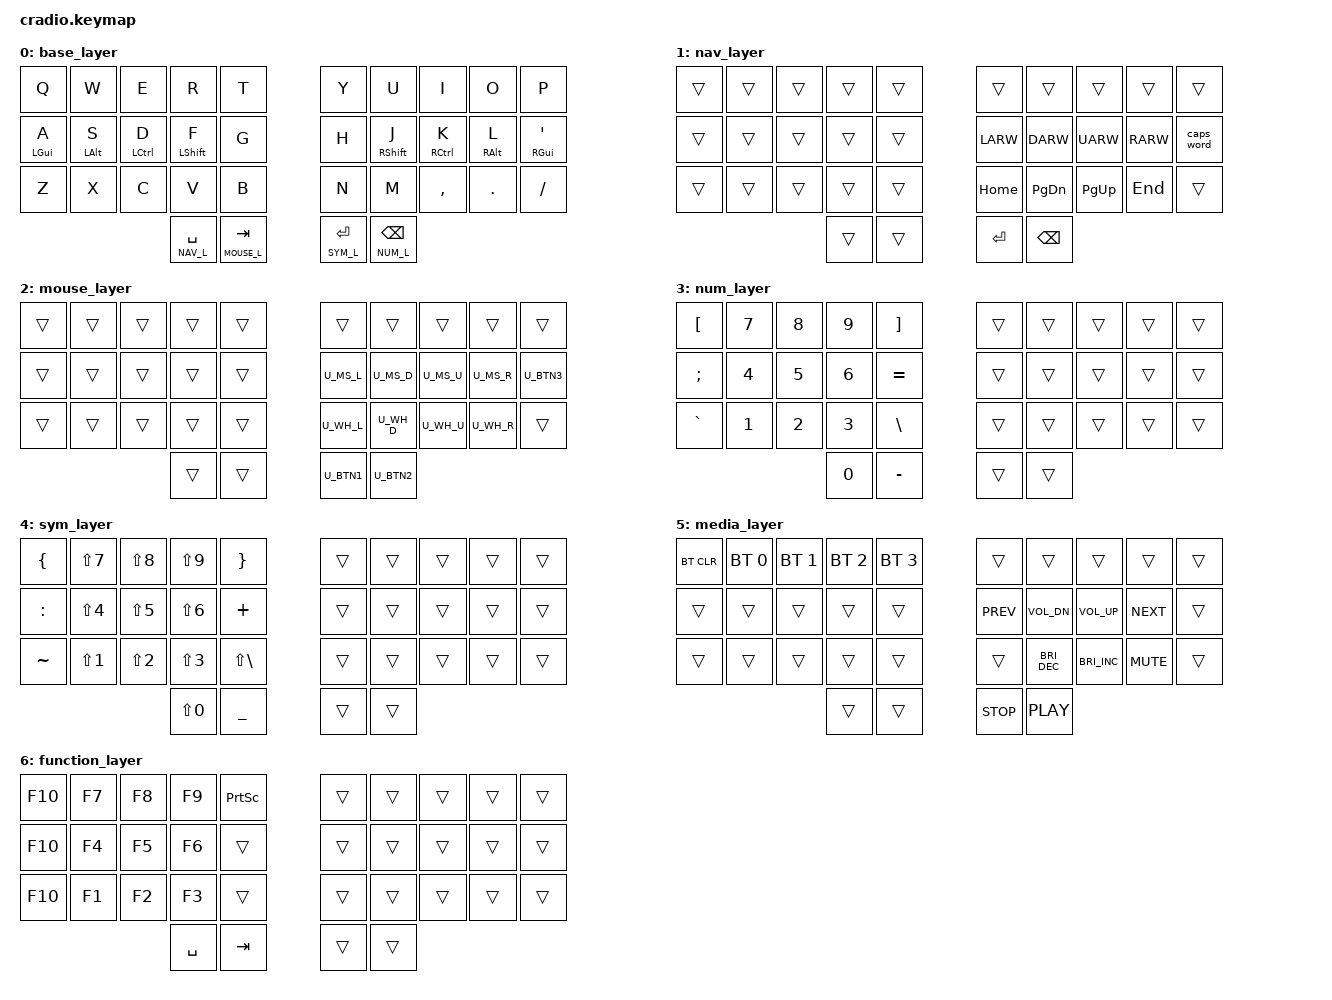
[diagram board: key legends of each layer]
/*
 * Copyright (c) 2020 The ZMK Contributors
 *
 * SPDX-License-Identifier: MIT
 */

#include <behaviors.dtsi>
#include <dt-bindings/zmk/keys.h>
#include <dt-bindings/zmk/bt.h>

#include "mouse.dtsi"
#include "combos.dtsi"

#include "../zmk-nodefree-config/keypos_def/keypos_34keys.h"
#define KEYS_L LT0 LT1 LT2 LT3 LT4 LM0 LM1 LM2 LM3 LM4 LB0 LB1 LB2 LB3 LB4 
#define KEYS_R RT0 RT1 RT2 RT3 RT4 RM0 RM1 RM2 RM3 RM4 RB0 RB1 RB2 RB3 RB4 
#define KEYS_T LH0 LH1 RH0 RH1 

// Layers Number
#define BASE_L 0
#define NAV_L 1
#define MOUSE_L 2
#define NUM_L 3
#define SYM_L 4
#define MEDIA_L 5
#define FUNC_L 6

// Using layer taps on thumbs, having quick tap as well helps w/ repeating space/backspace
&lt {
    tapping-term-ms = <175>; 
    quick-tap-ms = <200>;
};

/ {
    behaviors {
        hml: homerow_mods_left {
            compatible = "zmk,behavior-hold-tap";
            label = "homerow mods left";
            #binding-cells = <2>;
            bindings = <&kp>, <&kp>;

            flavor = "balanced";
            tapping-term-ms = <280>;
            quick-tap-ms = <175>;
            // global-quick-tap-ms = <150>;
            hold-trigger-key-positions = <KEYS_R KEYS_T>;
            hold-trigger-on-release;
        };
        hmr: homerow_mods_right {
            compatible = "zmk,behavior-hold-tap";
            label = "homerow mods right";
            #binding-cells = <2>;
            bindings = <&kp>, <&kp>;

            flavor = "balanced";
            tapping-term-ms = <280>;
            quick-tap-ms = <175>;
            // global-quick-tap-ms = <150>;
            hold-trigger-key-positions = <KEYS_L KEYS_T>;
            hold-trigger-on-release;
        };
        hml_s: homerow_mods_left_shift {
            compatible = "zmk,behavior-hold-tap";
            label = "homerow mods left";
            #binding-cells = <2>;
            bindings = <&kp>, <&kp>;

            flavor = "balanced";
            tapping-term-ms = <280>;
            quick-tap-ms = <125>;
            hold-trigger-key-positions = <KEYS_R KEYS_T>;
            hold-trigger-on-release;
        };
        hmr_s: homerow_mods_right_shift {
            compatible = "zmk,behavior-hold-tap";
            label = "homerow mods right";
            #binding-cells = <2>;
            bindings = <&kp>, <&kp>;

            flavor = "balanced";
            tapping-term-ms = <280>;
            quick-tap-ms = <125>;
            hold-trigger-key-positions = <KEYS_L KEYS_T>;
            hold-trigger-on-release;
        };
    };

    combos {
        compatible = "zmk,combos";
        combo_layer_media {
            timeout-ms = <50>;

            key-positions = <LH0 LH1>;
            bindings = <&lt MEDIA_L ESC>;
        };
        combo_layer_func {
            timeout-ms = <50>;

            key-positions = <RH0 RH1>;
            bindings = <&lt FUNC_L DEL>;
        };
    };

    keymap {
        compatible = "zmk,keymap";

        base_layer {
            bindings = <
    // ╭─────────────┬─────────────┬─────────────┬────────────────┬────────────────╮   ╭────────────────┬───────────────┬─────────────┬─────────────┬─────────────╮
          &kp Q         &kp W         &kp E          &kp R             &kp T                &kp Y          &kp U            &kp I         &kp O         &kp P
    // ├─────────────┼─────────────┼─────────────┼────────────────┼────────────────┤   ├────────────────┼───────────────┼─────────────┼─────────────┼─────────────┤
         &hml LGUI A   &hml LALT S   &hml LCTRL D  &hml_s LSHFT F      &kp G                &kp H         &hmr_s RSHFT J   &hmr RCTRL K  &hmr RALT L  &hmr RGUI QUOT
    // ├─────────────┼─────────────┼─────────────┼────────────────┼────────────────┤   ├────────────────┼───────────────┼─────────────┼─────────────┼─────────────┤
          &kp Z         &kp X         &kp C          &kp V             &kp B                &kp N          &kp M          &kp COMMA     &kp DOT       &kp FSLH
    // ╰─────────────┴─────────────┴─────────────┼────────────────┼────────────────┤   ├────────────────┼───────────────┼─────────────┴─────────────┴─────────────╯
                                                  &lt NAV_L SPACE   &lt MOUSE_L TAB      &lt SYM_L ENTER  &lt NUM_L BKSP  
    //                                           ╰────────────────┴────────────────╯   ╰────────────────┴───────────────╯
            >;
        };

        nav_layer { // 1
            bindings = <
    // ╭─────────────┬─────────────┬─────────────┬────────────────┬────────────────╮   ╭────────────────┬───────────────┬─────────────┬─────────────┬─────────────╮
          &trans         &trans         &trans         &trans         &trans               &trans            &trans         &trans        &trans       &trans
    // ├─────────────┼─────────────┼─────────────┼────────────────┼────────────────┤   ├────────────────┼───────────────┼─────────────┼─────────────┼─────────────┤
          &trans         &trans         &trans         &trans         &trans               &kp LARW          &kp DARW       &kp UARW      &kp RARW     &caps_word
    // ├─────────────┼─────────────┼─────────────┼────────────────┼────────────────┤   ├────────────────┼───────────────┼─────────────┼─────────────┼─────────────┤
          &trans         &trans         &trans         &trans         &trans               &kp HOME          &kp PG_DN      &kp PG_UP     &kp END      &trans
    // ├─────────────┼─────────────┼─────────────┼────────────────┼────────────────┤   ├────────────────┼───────────────┼─────────────┼─────────────┼─────────────┤
                                                       &trans         &trans               &kp ENTER         &kp BKSP       
    //                                           ╰────────────────┴────────────────╯   ╰────────────────┴───────────────╯
            >;
        };

        mouse_layer { // 2
            bindings = <
    // ╭─────────────┬─────────────┬─────────────┬────────────────┬────────────────╮   ╭────────────────┬───────────────┬─────────────┬─────────────┬─────────────╮
           &trans        &trans        &trans         &trans           &trans              &trans          &trans          &trans        &trans         &trans
    // ├─────────────┼─────────────┼─────────────┼────────────────┼────────────────┤   ├────────────────┼───────────────┼─────────────┼─────────────┼─────────────┤
           &trans        &trans        &trans         &trans           &trans             U_MS_L           U_MS_D          U_MS_U        U_MS_R         U_BTN3
    // ├─────────────┼─────────────┼─────────────┼────────────────┼────────────────┤   ├────────────────┼───────────────┼─────────────┼─────────────┼─────────────┤
           &trans        &trans        &trans         &trans           &trans             U_WH_L           U_WH_D          U_WH_U        U_WH_R        &trans
    // ├─────────────┼─────────────┼─────────────┼────────────────┼────────────────┤   ├────────────────┼───────────────┼─────────────┼─────────────┼─────────────┤
                                                      &trans           &trans             U_BTN1           U_BTN2       
    //                                           ╰────────────────┴────────────────╯   ╰────────────────┴───────────────╯
            >;
        };

        num_layer { // 3
            bindings = <
    // ╭─────────────┬─────────────┬─────────────┬────────────────┬────────────────╮   ╭────────────────┬───────────────┬─────────────┬─────────────┬─────────────╮
           &kp LBKT      &kp N7       &kp N8          &kp N9          &kp RBKT             &trans           &trans          &trans        &trans        &trans
    // ├─────────────┼─────────────┼─────────────┼────────────────┼────────────────┤   ├────────────────┼───────────────┼─────────────┼─────────────┼─────────────┤
           &kp SEMI      &kp N4       &kp N5          &kp N6          &kp EQUAL            &trans           &trans          &trans        &trans        &trans
    // ├─────────────┼─────────────┼─────────────┼────────────────┼────────────────┤   ├────────────────┼───────────────┼─────────────┼─────────────┼─────────────┤
           &kp GRAVE     &kp N1       &kp N2          &kp N3          &kp BSLH             &trans           &trans          &trans        &trans        &trans
    // ├─────────────┼─────────────┼─────────────┼────────────────┼────────────────┤   ├────────────────┼───────────────┼─────────────┼─────────────┼─────────────┤
                                                      &kp N0          &kp MINUS            &trans           &trans        
    //                                           ╰────────────────┴────────────────╯   ╰────────────────┴───────────────╯
            >;
        };

        sym_layer { // 4
            bindings = <
    // ╭─────────────┬─────────────┬─────────────┬────────────────┬────────────────╮   ╭────────────────┬───────────────┬─────────────┬─────────────┬─────────────╮
           &kp LBRC    &kp LS(N7)     &kp LS(N8)    &kp LS(N9)        &kp RBRC             &trans           &trans          &trans        &trans        &trans
    // ├─────────────┼─────────────┼─────────────┼────────────────┼────────────────┤   ├────────────────┼───────────────┼─────────────┼─────────────┼─────────────┤
           &kp COLON   &kp LS(N4)     &kp LS(N5)    &kp LS(N6)        &kp PLUS             &trans           &trans          &trans        &trans        &trans
    // ├─────────────┼─────────────┼─────────────┼────────────────┼────────────────┤   ├────────────────┼───────────────┼─────────────┼─────────────┼─────────────┤
           &kp TILDE   &kp LS(N1)     &kp LS(N2)    &kp LS(N3)        &kp LS(BSLH)         &trans           &trans          &trans        &trans        &trans
    // ├─────────────┼─────────────┼─────────────┼────────────────┼────────────────┤   ├────────────────┼───────────────┼─────────────┼─────────────┼─────────────┤
                                                    &kp LS(N0)        &kp UNDER            &trans           &trans          
    //                                           ╰────────────────┴────────────────╯   ╰────────────────┴───────────────╯
            >;
        };

        media_layer { // 5
            bindings = <
    // ╭─────────────┬─────────────┬─────────────┬────────────────┬────────────────╮   ╭────────────────┬───────────────┬─────────────┬─────────────┬─────────────╮
          &bt BT_CLR   &bt BT_SEL 0  &bt BT_SEL 1   &bt BT_SEL 2     &bt BT_SEL 3         &trans           &trans         &trans         &trans       &trans
    // ├─────────────┼─────────────┼─────────────┼────────────────┼────────────────┤   ├────────────────┼───────────────┼─────────────┼─────────────┼─────────────┤
          &trans         &trans        &trans         &trans         &trans               &kp C_PREV      &kp C_VOL_DN    &kp C_VOL_UP   &kp C_NEXT     &trans
    // ├─────────────┼─────────────┼─────────────┼────────────────┼────────────────┤   ├────────────────┼───────────────┼─────────────┼─────────────┼─────────────┤
          &trans       &trans         &trans        &trans           &trans               &trans          &kp C_BRI_DEC   &kp C_BRI_INC  &kp C_MUTE     &trans
    // ├─────────────┼─────────────┼─────────────┼────────────────┼────────────────┤   ├────────────────┼───────────────┼─────────────┼─────────────┼─────────────┤
                                                    &trans           &trans               &kp C_STOP       &kp C_PLAY     
    //                                           ╰────────────────┴────────────────╯   ╰────────────────┴───────────────╯
            >;
        };

        function_layer { // 6
            bindings = <
    // ╭─────────────┬─────────────┬─────────────┬────────────────┬────────────────╮   ╭────────────────┬───────────────┬─────────────┬─────────────┬─────────────╮
           &kp F10      &kp F7         &kp F8        &kp F9         &kp PRINTSCREEN         &trans            &trans          &trans       &trans       &trans
    // ├─────────────┼─────────────┼─────────────┼────────────────┼────────────────┤   ├────────────────┼───────────────┼─────────────┼─────────────┼─────────────┤
           &kp F10      &kp F4         &kp F5        &kp F6         &trans                  &trans            &trans          &trans       &trans       &trans
    // ├─────────────┼─────────────┼─────────────┼────────────────┼────────────────┤   ├────────────────┼───────────────┼─────────────┼─────────────┼─────────────┤
           &kp F10      &kp F1         &kp F2        &kp F3         &trans                  &trans            &trans          &trans       &trans       &trans
    // ├─────────────┼─────────────┼─────────────┼────────────────┼────────────────┤   ├────────────────┼───────────────┼─────────────┼─────────────┼─────────────┤
                                                     &kp SPACE      &kp TAB                 &trans            &trans          
    //                                           ╰────────────────┴────────────────╯   ╰────────────────┴───────────────╯
            >;
        };
    };
};
